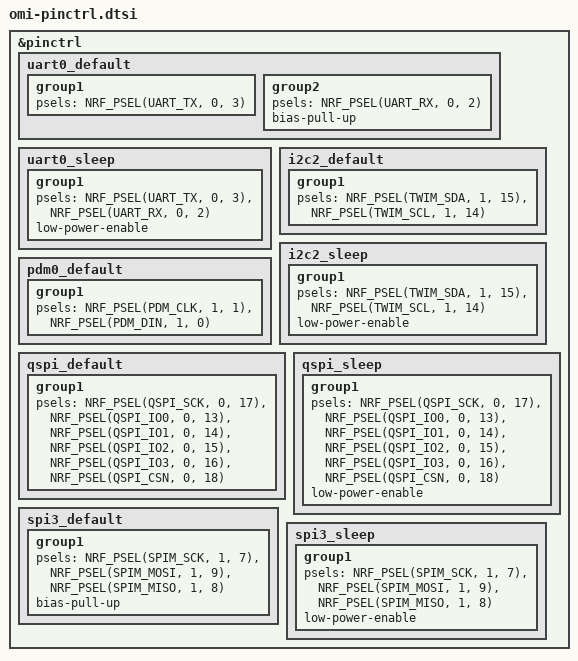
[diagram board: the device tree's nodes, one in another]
&pinctrl {
	uart0_default: uart0_default {
		group1 {
			psels = <NRF_PSEL(UART_TX, 0, 3)>;
		};
		group2 {
			psels = <NRF_PSEL(UART_RX, 0, 2)>;
			bias-pull-up;
		};
	};
	
	uart0_sleep: uart0_sleep {
		group1 {
			psels = <NRF_PSEL(UART_TX, 0, 3)>,
			<NRF_PSEL(UART_RX, 0, 2)>;
			low-power-enable;
		};
	};
	
	i2c2_default: i2c2_default {
		group1 {
			psels = <NRF_PSEL(TWIM_SDA, 1, 15)>,
			<NRF_PSEL(TWIM_SCL, 1, 14)>;
		};
	};
	
	i2c2_sleep: i2c2_sleep {
		group1 {
			psels = <NRF_PSEL(TWIM_SDA, 1, 15)>,
			<NRF_PSEL(TWIM_SCL, 1, 14)>;
			low-power-enable;
		};
	};
	
	pdm0_default: pdm0_default {
		group1 {
			psels = <NRF_PSEL(PDM_CLK, 1, 1)>,
			<NRF_PSEL(PDM_DIN, 1, 0)>;
		};
	};
	
	qspi_default: qspi_default {
		group1 {
			psels = <NRF_PSEL(QSPI_SCK, 0, 17)>,
			<NRF_PSEL(QSPI_IO0, 0, 13)>,
			<NRF_PSEL(QSPI_IO1, 0, 14)>,
			<NRF_PSEL(QSPI_IO2, 0, 15)>,
			<NRF_PSEL(QSPI_IO3, 0, 16)>,
			<NRF_PSEL(QSPI_CSN, 0, 18)>;
		};
	};
	
	qspi_sleep: qspi_sleep {
		group1 {
			psels = <NRF_PSEL(QSPI_SCK, 0, 17)>,
			<NRF_PSEL(QSPI_IO0, 0, 13)>,
			<NRF_PSEL(QSPI_IO1, 0, 14)>,
			<NRF_PSEL(QSPI_IO2, 0, 15)>,
			<NRF_PSEL(QSPI_IO3, 0, 16)>,
			<NRF_PSEL(QSPI_CSN, 0, 18)>;
			low-power-enable;
		};
	};
	
	spi3_default: spi3_default {
		group1 {
			psels = <NRF_PSEL(SPIM_SCK, 1, 7)>,
			<NRF_PSEL(SPIM_MOSI, 1, 9)>,
			<NRF_PSEL(SPIM_MISO, 1, 8)>;
			bias-pull-up;
		};
	};
	
	spi3_sleep: spi3_sleep {
		group1 {
			psels = <NRF_PSEL(SPIM_SCK, 1, 7)>,
			<NRF_PSEL(SPIM_MOSI, 1, 9)>,
			<NRF_PSEL(SPIM_MISO, 1, 8)>;
			low-power-enable;
		};
	};
};
